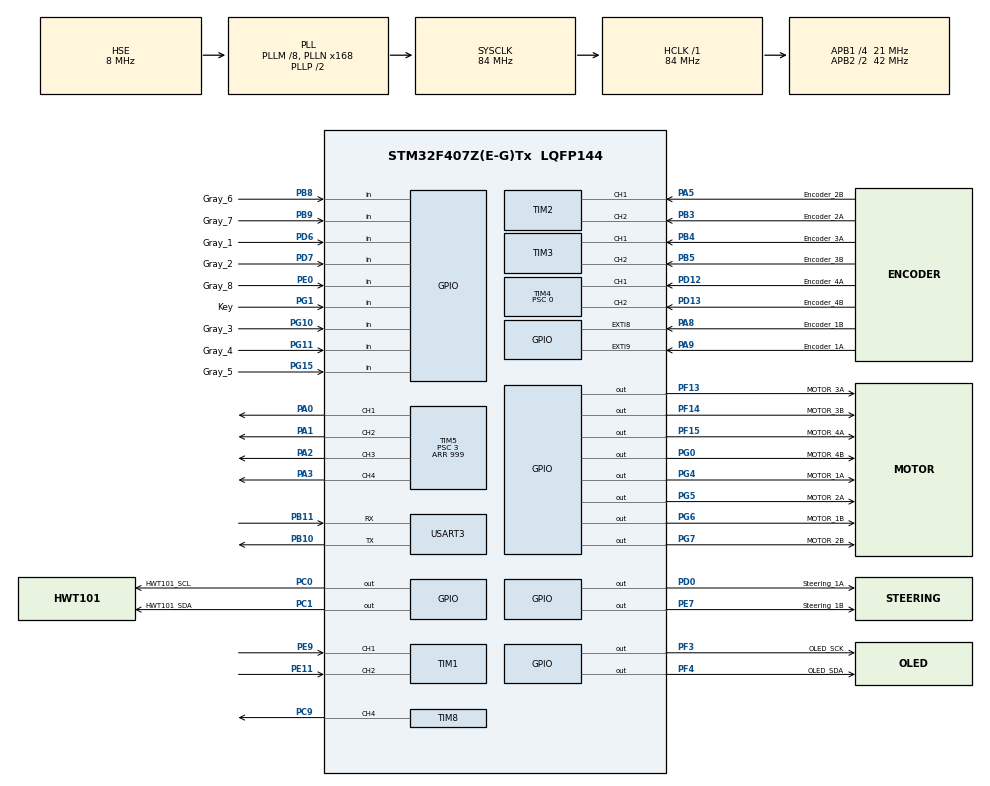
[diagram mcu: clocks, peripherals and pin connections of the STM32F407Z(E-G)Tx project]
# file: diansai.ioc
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Dma.Request0=USART3_RX
Dma.Request1=USART3_TX
Dma.USART3_RX.0.Direction=DMA_PERIPH_TO_MEMORY
Dma.USART3_RX.0.FIFOMode=DMA_FIFOMODE_DISABLE
Dma.USART3_RX.0.Instance=DMA1_Stream1
Dma.USART3_RX.0.MemDataAlignment=DMA_MDATAALIGN_BYTE
Dma.USART3_RX.0.MemInc=DMA_MINC_ENABLE
Dma.USART3_RX.0.Mode=DMA_NORMAL
Dma.USART3_RX.0.PeriphDataAlignment=DMA_PDATAALIGN_BYTE
Dma.USART3_RX.0.PeriphInc=DMA_PINC_DISABLE
Dma.USART3_RX.0.Priority=DMA_PRIORITY_LOW
Dma.USART3_TX.1.Direction=DMA_MEMORY_TO_PERIPH
Dma.USART3_TX.1.FIFOMode=DMA_FIFOMODE_DISABLE
Dma.USART3_TX.1.Instance=DMA1_Stream3
Dma.USART3_TX.1.MemDataAlignment=DMA_MDATAALIGN_BYTE
Dma.USART3_TX.1.MemInc=DMA_MINC_ENABLE
Dma.USART3_TX.1.Mode=DMA_NORMAL
Dma.USART3_TX.1.PeriphDataAlignment=DMA_PDATAALIGN_BYTE
Dma.USART3_TX.1.PeriphInc=DMA_PINC_DISABLE
Dma.USART3_TX.1.Priority=DMA_PRIORITY_LOW
Mcu.Family=STM32F4
Mcu.Name=STM32F407Z(E-G)Tx
Mcu.Package=LQFP144
NVIC.DMA1_Stream1_IRQn=true\:0\:0\:false\:false\:true\:false\:true\:true
NVIC.DMA1_Stream3_IRQn=true\:0\:0\:false\:false\:true\:false\:true\:true
NVIC.EXTI9_5_IRQn=true\:0\:0\:false\:false\:true\:true\:true\:true
NVIC.PriorityGroup=NVIC_PRIORITYGROUP_4
NVIC.TIM6_DAC_IRQn=true\:1\:0\:true\:false\:true\:true\:true\:true
NVIC.USART3_IRQn=true\:0\:0\:false\:false\:true\:true\:true\:true
PA0-WKUP.Signal=S_TIM5_CH1
PA1.Signal=S_TIM5_CH2
PA13.Mode=Serial_Wire
PA13.Signal=SYS_JTMS-SWDIO
PA14.Mode=Serial_Wire
PA14.Signal=SYS_JTCK-SWCLK
PA2.Signal=S_TIM5_CH3
PA3.Signal=S_TIM5_CH4
PA5.GPIO_Label=Encoder_2B
PA5.Signal=S_TIM2_CH1_ETR
PA8.GPIO_Label=Encoder_1B
PA8.GPIO_ModeDefaultEXTI=GPIO_MODE_IT_RISING_FALLING
PA8.Signal=GPXTI8
PA9.GPIO_Label=Encoder_1A
PA9.GPIO_ModeDefaultEXTI=GPIO_MODE_IT_RISING_FALLING
PA9.Signal=GPXTI9
PB10.Mode=Asynchronous
PB10.Signal=USART3_TX
PB11.Mode=Asynchronous
PB11.Signal=USART3_RX
PB3.GPIO_Label=Encoder_2A
PB3.Signal=S_TIM2_CH2
PB4.GPIO_Label=Encoder_3A
PB4.Signal=S_TIM3_CH1
PB5.GPIO_Label=Encoder_3B
PB5.Signal=S_TIM3_CH2
PB8.GPIO_Label=Gray_6
PB8.Signal=GPIO_Input
PB9.GPIO_Label=Gray_7
PB9.Signal=GPIO_Input
PC0.GPIO_Label=HWT101_SCL
PC0.GPIO_ModeDefaultOutputPP=GPIO_MODE_OUTPUT_OD
PC0.GPIO_OutputLevel=GPIO_PIN_SET
PC0.GPIO_PuPd=GPIO_PULLUP
PC0.GPIO_Speed=GPIO_SPEED_FREQ_HIGH
PC0.Signal=GPIO_Output
PC1.GPIO_Label=HWT101_SDA
PC1.GPIO_ModeDefaultOutputPP=GPIO_MODE_OUTPUT_OD
PC1.GPIO_OutputLevel=GPIO_PIN_SET
PC1.GPIO_PuPd=GPIO_PULLUP
PC1.GPIO_Speed=GPIO_SPEED_FREQ_HIGH
PC1.Signal=GPIO_Output
PC9.Signal=S_TIM8_CH4
PD0.GPIO_Label=Steering_1A
PD0.Signal=GPIO_Output
PD12.GPIO_Label=Encoder_4A
PD12.Signal=S_TIM4_CH1
PD13.GPIO_Label=Encoder_4B
PD13.Signal=S_TIM4_CH2
PD6.GPIO_Label=Gray_1
PD6.Signal=GPIO_Input
PD7.GPIO_Label=Gray_2
PD7.Signal=GPIO_Input
PE0.GPIO_Label=Gray_8
PE0.Signal=GPIO_Input
PE11.Signal=S_TIM1_CH2
PE7.GPIO_Label=Steering_1B
PE7.Signal=GPIO_Output
PE9.Signal=S_TIM1_CH1
PF13.GPIO_Label=MOTOR_3A
PF13.Signal=GPIO_Output
PF14.GPIO_Label=MOTOR_3B
PF14.Signal=GPIO_Output
PF15.GPIO_Label=MOTOR_4A
PF15.Signal=GPIO_Output
PF3.GPIO_Label=OLED_SCK
PF3.Signal=GPIO_Output
PF4.GPIO_Label=OLED_SDA
PF4.Signal=GPIO_Output
PG0.GPIO_Label=MOTOR_4B
PG0.Signal=GPIO_Output
PG1.GPIO_Label=Key
PG1.GPIO_PuPd=GPIO_PULLUP
PG1.Signal=GPIO_Input
PG10.GPIO_Label=Gray_3
PG10.Signal=GPIO_Input
PG11.GPIO_Label=Gray_4
PG11.Signal=GPIO_Input
PG15.GPIO_Label=Gray_5
PG15.Signal=GPIO_Input
PG4.GPIO_Label=MOTOR_1A
PG4.Signal=GPIO_Output
PG5.GPIO_Label=MOTOR_2A
PG5.Signal=GPIO_Output
PG6.GPIO_Label=MOTOR_1B
PG6.Signal=GPIO_Output
PG7.GPIO_Label=MOTOR_2B
PG7.Signal=GPIO_Output
PH0-OSC_IN.Mode=HSE-External-Oscillator
PH0-OSC_IN.Signal=RCC_OSC_IN
PH1-OSC_OUT.Mode=HSE-External-Oscillator
PH1-OSC_OUT.Signal=RCC_OSC_OUT
ProjectManager.HeapSize=0x200
ProjectManager.StackSize=0x400
ProjectManager.TargetToolchain=MDK-ARM V5.32
RCC.48MHZClocksFreq_Value=42000000
RCC.AHBFreq_Value=84000000
RCC.APB1CLKDivider=RCC_HCLK_DIV4
RCC.APB1Freq_Value=21000000
RCC.APB1TimFreq_Value=42000000
RCC.APB2CLKDivider=RCC_HCLK_DIV2
RCC.APB2Freq_Value=42000000
RCC.APB2TimFreq_Value=84000000
RCC.CortexFreq_Value=84000000
RCC.HCLKFreq_Value=84000000
RCC.HSE_VALUE=8000000
RCC.HSI_VALUE=16000000
RCC.LSE_VALUE=32768
RCC.PLLM=8
RCC.PLLN=168
RCC.PLLSourceVirtual=RCC_PLLSOURCE_HSE
RCC.SYSCLKFreq_VALUE=84000000
RCC.SYSCLKSource=RCC_SYSCLKSOURCE_PLLCLK
RCC.VCOOutputFreq_Value=168000000
SH.S_TIM1_CH1.0=TIM1_CH1,Encoder_Interface
SH.S_TIM1_CH2.0=TIM1_CH2,Encoder_Interface
SH.S_TIM2_CH1_ETR.0=TIM2_CH1,Encoder_Interface
SH.S_TIM2_CH2.0=TIM2_CH2,Encoder_Interface
SH.S_TIM3_CH1.0=TIM3_CH1,Encoder_Interface
SH.S_TIM3_CH2.0=TIM3_CH2,Encoder_Interface
SH.S_TIM4_CH1.0=TIM4_CH1,Encoder_Interface
SH.S_TIM4_CH2.0=TIM4_CH2,Encoder_Interface
SH.S_TIM5_CH1.0=TIM5_CH1,PWM Generation1 CH1
SH.S_TIM5_CH2.0=TIM5_CH2,PWM Generation2 CH2
SH.S_TIM5_CH3.0=TIM5_CH3,PWM Generation3 CH3
SH.S_TIM5_CH4.0=TIM5_CH4,PWM Generation4 CH4
SH.S_TIM8_CH4.0=TIM8_CH4,PWM Generation4 CH4
TIM1.EncoderMode=TIM_ENCODERMODE_TI12
TIM2.EncoderMode=TIM_ENCODERMODE_TI12
TIM3.EncoderMode=TIM_ENCODERMODE_TI12
TIM4.EncoderMode=TIM_ENCODERMODE_TI12
TIM4.Period=65535
TIM4.Prescaler=0
TIM5.Channel-PWM\ Generation1\ CH1=TIM_CHANNEL_1
TIM5.Channel-PWM\ Generation2\ CH2=TIM_CHANNEL_2
TIM5.Channel-PWM\ Generation3\ CH3=TIM_CHANNEL_3
TIM5.Channel-PWM\ Generation4\ CH4=TIM_CHANNEL_4
TIM5.Period=999
TIM5.Prescaler=3
TIM6.Period=99
TIM6.Prescaler=4199
TIM8.Channel-PWM\ Generation4\ CH4=TIM_CHANNEL_4
TIM8.Period=999
TIM8.Prescaler=3
USART3.VirtualMode=VM_ASYNC
VP_TIM5_VS_ClockSourceINT.Mode=Internal
VP_TIM6_VS_ClockSourceINT.Mode=Enable_Timer
VP_TIM8_VS_ClockSourceINT.Mode=Internal
board=custom

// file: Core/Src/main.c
/* USER CODE BEGIN Header */
/**
  ******************************************************************************
  * @file           : main.c
  * @brief          : Main program body
  ******************************************************************************
  * @attention
  *
  * Copyright (c) 2026 STMicroelectronics.
  * All rights reserved.
  *
  * This software is licensed under terms that can be found in the LICENSE file
  * in the root directory of this software component.
  * If no LICENSE file comes with this software, it is provided AS-IS.
  *
  ******************************************************************************
  */
/* USER CODE END Header */
#include "main.h"
#include "dma.h"
#include "tim.h"
#include "usart.h"
#include "gpio.h"

/* USER CODE BEGIN Includes */
#include "My_app.h"

/* USER CODE END Includes */

void SystemClock_Config(void);

int main(void)
{

  /* USER CODE BEGIN 1 */
  /* 应用状态已封装到 My_app 模块，main 不持有业务变量或中断共享状态。 */
  /* USER CODE END 1 */

  /* MCU Configuration--------------------------------------------------------*/

  /* Reset of all peripherals, Initializes the Flash interface and the Systick. */
  HAL_Init();

  /* USER CODE BEGIN Init */
  /*
   * HAL_Init 已完成外设复位、Flash 接口和 1 ms SysTick 基础初始化。
   * 此处不启动业务模块，所有依赖系统时钟的外设必须等待时钟配置完成。
   */
  /* USER CODE END Init */

  /* Configure the system clock */
  SystemClock_Config();

  /* USER CODE BEGIN SysInit */
  /*
   * 系统时钟已切换到 HSE+PLL；随后由 CubeMX 初始化 GPIO、DMA、底盘 PWM TIM5、
   * 控制周期 TIM6、转向编码器 TIM1、底盘编码器 TIM2/TIM3/TIM4 和转向 PWM TIM8。
   * DMA 必须先于 USART3 业务接收启动；全部编码器和执行器初始化完成后，应用层
   * 才启动 TIM6 中断，避免周期回调读取未初始化状态。
   */
  /* USER CODE END SysInit */

  /* Initialize all configured peripherals */
  MX_GPIO_Init();
  MX_DMA_Init();
  MX_TIM5_Init();
  MX_USART3_UART_Init();
  MX_TIM6_Init();
  MX_TIM1_Init();
  MX_TIM4_Init();
  MX_TIM2_Init();
  MX_TIM3_Init();
  MX_TIM8_Init();
  /* USER CODE BEGIN 2 */
  /*
   * 应用层按“通信与传感器 -> 显示 -> 执行器与反馈 -> 控制参数 -> TIM6 中断”
   * 的依赖顺序启动。任何关键模块失败都进入统一停机路径，不进入业务主循环。
   */
  if (My_app_init_My() != HAL_OK)
  {
    Error_Handler();
  }
  /* USER CODE END 2 */

  /* Infinite loop */
  while (1)
  {

    /* USER CODE BEGIN 3 */

    /*
     * 执行一次非阻塞应用调度：解析姿态与通信、刷新 OLED、扫描按键并推进任务
     * 状态机。循环没有固定周期保证，所有 10 ms 实时控制均由 TIM6 中断承担。
     */
    My_app_process_My();
    }
  /* USER CODE END 3 */
}

void SystemClock_Config(void)
{
  RCC_OscInitTypeDef RCC_OscInitStruct = {0};
  RCC_ClkInitTypeDef RCC_ClkInitStruct = {0};

  /** Configure the main internal regulator output voltage
  */
  __HAL_RCC_PWR_CLK_ENABLE();
  __HAL_PWR_VOLTAGESCALING_CONFIG(PWR_REGULATOR_VOLTAGE_SCALE1);

  /** Initializes the RCC Oscillators according to the specified parameters
  * in the RCC_OscInitTypeDef structure.
  */
  RCC_OscInitStruct.OscillatorType = RCC_OSCILLATORTYPE_HSE;
  RCC_OscInitStruct.HSEState = RCC_HSE_ON;
  RCC_OscInitStruct.PLL.PLLState = RCC_PLL_ON;
  RCC_OscInitStruct.PLL.PLLSource = RCC_PLLSOURCE_HSE;
  RCC_OscInitStruct.PLL.PLLM = 8;
  RCC_OscInitStruct.PLL.PLLN = 168;
  RCC_OscInitStruct.PLL.PLLP = RCC_PLLP_DIV2;
  RCC_OscInitStruct.PLL.PLLQ = 4;
  if (HAL_RCC_OscConfig(&RCC_OscInitStruct) != HAL_OK)
  {
    Error_Handler();
  }

  /** Initializes the CPU, AHB and APB buses clocks
  */
  RCC_ClkInitStruct.ClockType = RCC_CLOCKTYPE_HCLK|RCC_CLOCKTYPE_SYSCLK
                              |RCC_CLOCKTYPE_PCLK1|RCC_CLOCKTYPE_PCLK2;
  RCC_ClkInitStruct.SYSCLKSource = RCC_SYSCLKSOURCE_PLLCLK;
  RCC_ClkInitStruct.AHBCLKDivider = RCC_SYSCLK_DIV1;
  RCC_ClkInitStruct.APB1CLKDivider = RCC_HCLK_DIV4;
  RCC_ClkInitStruct.APB2CLKDivider = RCC_HCLK_DIV2;

  if (HAL_RCC_ClockConfig(&RCC_ClkInitStruct, FLASH_LATENCY_2) != HAL_OK)
  {
    Error_Handler();
  }
}

/* USER CODE BEGIN 4 */

/**
  * @brief HAL 定时器周期中断统一回调。
  * @details 中断来源为 TIM6 更新事件，触发周期为 10 ms。HAL 清除硬件标志后调用
  *          本函数，先采样 TIM1 编码器；任务 3 已确认时更新分段钢球外环；任务 4
  *          推进定时底盘曲线，任务 5/6 复用任务 2 循迹与终点判定并执行 S 型停车；
  *          任务 4/5 保持钢球 0 点，任务 6 保持启动帧平均目标。随后驱动转向位置
  *          内环和灰度循迹 PID。
  *          本函数会更新任务阶段、摄像头新鲜度、编码器、PID 和电机共享状态。
  *          调试数据使用 volatile 且字段为自然对齐的 16/32 位访问，但观察多个字段
  *          时仍可能跨越一次中断。中断内禁止阻塞、延时、打印、动态分配和长时运算。
  * @param htim 触发中断的定时器句柄
  */
void HAL_TIM_PeriodElapsedCallback(TIM_HandleTypeDef *htim)
{
  /* 先核对中断来源，只允许 TIM6 执行固定周期任务，避免其他定时器改写共享状态。 */
  if (htim->Instance == TIM6)
  {
    /*
     * 应用周期接口先采样 TIM1 编码器，再按已确认任务推进任务 3 分段钢球外环、
     * 任务 4 定时曲线、任务 5 稳定循迹或任务 6 启动目标循迹；任务 4/5 保持
     * 钢球 0 点，任务 6 保持启动帧平均目标。最后更新转向位置内环、灰度 PID 和
     * 电机输出。接口只执行常数时间计算，不包含延时、打印、动态分配
     * 或软件 I2C；摄像头字符解析固定留在主循环。
     */
    My_app_control_10ms_My();
  }
}

/* USER CODE END 4 */

void Error_Handler(void)
{
  __disable_irq();
  while (1)
  {
  }
}
